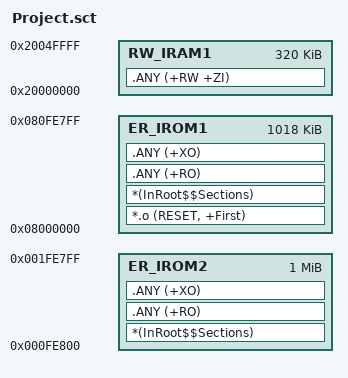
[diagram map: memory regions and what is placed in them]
; *************************************************************
; *** Scatter-Loading Description File generated by uVision ***
; *************************************************************

LR_IROM1 0x08000000 0x00100000  {    ; load region size_region
  ER_IROM1 0x08000000 0x000FE800  {  ; load address = execution address
   *.o (RESET, +First)
   *(InRoot$$Sections)
   .ANY (+RO)
   .ANY (+XO)
  }
    ER_IROM2 0x000FE800 0x00100000  {  ; load address = execution address
   *(InRoot$$Sections)
   .ANY (+RO)
   .ANY (+XO)
  }
  RW_IRAM1 0x20000000 0x00050000  {  ; RW data
   .ANY (+RW +ZI)
  }
}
